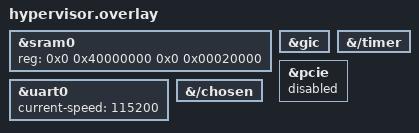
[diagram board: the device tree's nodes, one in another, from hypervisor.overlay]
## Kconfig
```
mainmenu "Zilch Zephyr guest"

source "$ZEPHYR_BASE/Kconfig.zephyr"
```

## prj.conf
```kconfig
CONFIG_CACHE_MANAGEMENT=n
CONFIG_ARMV8_A_NS=y
CONFIG_ARM_ARCH_TIMER=y
CONFIG_MULTITHREADING=y
CONFIG_MAIN_STACK_SIZE=1024
CONFIG_ISR_STACK_SIZE=512
CONFIG_IDLE_STACK_SIZE=256
CONFIG_SERIAL=y
CONFIG_UART_PL011=y
CONFIG_UART_INTERRUPT_DRIVEN=y
CONFIG_UART_USE_RUNTIME_CONFIGURE=n
CONFIG_CONSOLE=y
CONFIG_UART_CONSOLE=y
CONFIG_SHELL=y
CONFIG_SHELL_BACKEND_SERIAL=y
CONFIG_SHELL_BACKEND_SERIAL_INTERRUPT_DRIVEN=y
CONFIG_SHELL_BACKEND_SERIAL_API_INTERRUPT_DRIVEN=y
CONFIG_SHELL_BACKEND_SERIAL_FORCE_TX_BLOCKING_MODE=y
CONFIG_SHELL_PROMPT_UART="zilch:~$ "
CONFIG_PRINTK=y
CONFIG_BOOT_BANNER=n
CONFIG_LOG=n
CONFIG_ASSERT=n
CONFIG_INIT_STACKS=n
CONFIG_FPU=n
CONFIG_FPU_SHARING=n
CONFIG_SYS_CLOCK_HW_CYCLES_PER_SEC=24000000
```

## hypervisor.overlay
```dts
&sram0 {
	reg = <0x0 0x40000000 0x0 0x00020000>;
};

&gic {
	status = "okay";
};

&{/timer} {
	status = "okay";
};

&uart0 {
	status = "okay";
	current-speed = <115200>;
};

&pcie {
	status = "disabled";
};

&{/chosen} {
	/delete-property/ zephyr,flash;
	/delete-property/ zephyr,pcie-controller;
};
```

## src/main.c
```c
#include <zephyr/sys/printk.h>

int main(void)
{
    printk("Zilch Zephyr guest booted\n");
    return 0;
}
```
